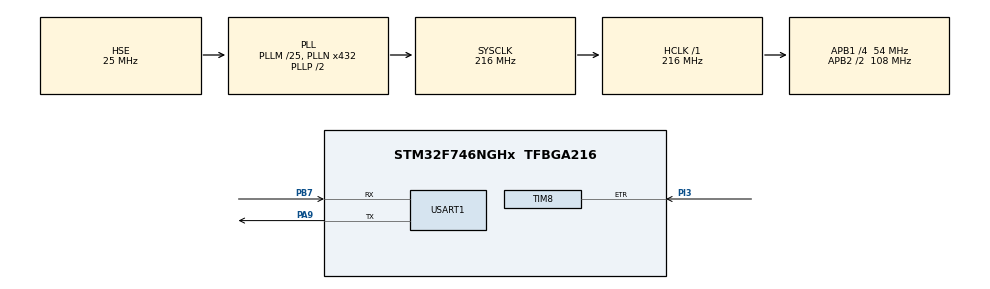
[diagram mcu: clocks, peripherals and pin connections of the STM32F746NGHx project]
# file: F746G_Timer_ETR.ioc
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Mcu.Family=STM32F7
Mcu.Name=STM32F746NGHx
Mcu.Package=TFBGA216
NVIC.PriorityGroup=NVIC_PRIORITYGROUP_4
NVIC.TIM8_UP_TIM13_IRQn=true\:0\:0\:false\:false\:true\:true\:true\:true
PA13.Mode=Serial_Wire
PA13.Signal=SYS_JTMS-SWDIO
PA14.Mode=Serial_Wire
PA14.Signal=SYS_JTCK-SWCLK
PA9.Mode=Asynchronous
PA9.Signal=USART1_TX
PB7.Mode=Asynchronous
PB7.Signal=USART1_RX
PH0/OSC_IN.Mode=HSE-External-Oscillator
PH0/OSC_IN.Signal=RCC_OSC_IN
PH1/OSC_OUT.Mode=HSE-External-Oscillator
PH1/OSC_OUT.Signal=RCC_OSC_OUT
PI3.Signal=S_TIM8_ETR
ProjectManager.HeapSize=0x200
ProjectManager.StackSize=0x400
ProjectManager.TargetToolchain=STM32CubeIDE
RCC.AHBFreq_Value=216000000
RCC.APB1CLKDivider=RCC_HCLK_DIV4
RCC.APB1Freq_Value=54000000
RCC.APB1TimFreq_Value=108000000
RCC.APB2CLKDivider=RCC_HCLK_DIV2
RCC.APB2Freq_Value=108000000
RCC.APB2TimFreq_Value=216000000
RCC.CortexFreq_Value=216000000
RCC.HCLKFreq_Value=216000000
RCC.HSE_VALUE=25000000
RCC.HSI_VALUE=16000000
RCC.LSE_VALUE=32768
RCC.PLLM=25
RCC.PLLN=432
RCC.PLLSourceVirtual=RCC_PLLSOURCE_HSE
RCC.SYSCLKFreq_VALUE=216000000
RCC.SYSCLKSource=RCC_SYSCLKSOURCE_PLLCLK
RCC.USBFreq_Value=216000000
RCC.VCOOutputFreq_Value=432000000
SH.S_TIM8_ETR.0=TIM8_ETR,ClockSourceETR_Mode2
TIM8.Period=9
USART1.VirtualMode-Asynchronous=VM_ASYNC
board=STM32F746G-DISCO

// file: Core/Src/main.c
/* USER CODE BEGIN Header */
/**
  ******************************************************************************
  * @file           : main.c
  * @brief          : Main program body
  ******************************************************************************
  * @attention
  *
  * Copyright (c) 2023 STMicroelectronics.
  * All rights reserved.
  *
  * This software is licensed under terms that can be found in the LICENSE file
  * in the root directory of this software component.
  * If no LICENSE file comes with this software, it is provided AS-IS.
  *
  ******************************************************************************
  */
/* USER CODE END Header */
#include "main.h"
#include "tim.h"
#include "usart.h"
#include "gpio.h"

/* USER CODE BEGIN Includes */
#include <stdio.h>
/* USER CODE END Includes */

/* USER CODE BEGIN PV */
uint8_t end_msg[35] = "Overflow Reached! Counter Reset!\n\r";
/* USER CODE END PV */

void SystemClock_Config(void);
/* USER CODE BEGIN PFP */
#ifdef __GNUC__
/* With GCC/RAISONANCE, small printf (option LD Linker->Libraries->Small printf
set to 'Yes') calls __io_putchar() */
#define PUTCHAR_PROTOTYPE int __io_putchar(int ch)
#else
#define PUTCHAR_PROTOTYPE int fputc(int ch, FILE *f)
#endif /* __GNUC__ */
/* USER CODE END PFP */

int main(void)
{
  /* USER CODE BEGIN 1 */
	uint16_t ticks = 0;
  /* USER CODE END 1 */

  /* MCU Configuration--------------------------------------------------------*/

  /* Reset of all peripherals, Initializes the Flash interface and the Systick. */
  HAL_Init();

  /* Configure the system clock */
  SystemClock_Config();

  /* Initialize all configured peripherals */
  MX_GPIO_Init();
  MX_TIM8_Init();
  MX_USART1_UART_Init();
  /* USER CODE BEGIN 2 */
  HAL_TIM_Base_Start_IT(&htim8);
  /* USER CODE END 2 */

  /* Infinite loop */
  while (1)
  {

    /* USER CODE BEGIN 3 */
    // Read The Counter Ticks Register
	ticks = TIM8->CNT;
	// Print The Ticks Count Via UART1
	printf("Ticks = %d\n\r", ticks);
	HAL_Delay(250);
  }
  /* USER CODE END 3 */
}

void SystemClock_Config(void)
{
  RCC_OscInitTypeDef RCC_OscInitStruct = {0};
  RCC_ClkInitTypeDef RCC_ClkInitStruct = {0};

  /** Configure the main internal regulator output voltage
  */
  __HAL_RCC_PWR_CLK_ENABLE();
  __HAL_PWR_VOLTAGESCALING_CONFIG(PWR_REGULATOR_VOLTAGE_SCALE1);

  /** Initializes the RCC Oscillators according to the specified parameters
  * in the RCC_OscInitTypeDef structure.
  */
  RCC_OscInitStruct.OscillatorType = RCC_OSCILLATORTYPE_HSE;
  RCC_OscInitStruct.HSEState = RCC_HSE_ON;
  RCC_OscInitStruct.PLL.PLLState = RCC_PLL_ON;
  RCC_OscInitStruct.PLL.PLLSource = RCC_PLLSOURCE_HSE;
  RCC_OscInitStruct.PLL.PLLM = 25;
  RCC_OscInitStruct.PLL.PLLN = 432;
  RCC_OscInitStruct.PLL.PLLP = RCC_PLLP_DIV2;
  RCC_OscInitStruct.PLL.PLLQ = 2;
  if (HAL_RCC_OscConfig(&RCC_OscInitStruct) != HAL_OK)
  {
    Error_Handler();
  }

  /** Activate the Over-Drive mode
  */
  if (HAL_PWREx_EnableOverDrive() != HAL_OK)
  {
    Error_Handler();
  }

  /** Initializes the CPU, AHB and APB buses clocks
  */
  RCC_ClkInitStruct.ClockType = RCC_CLOCKTYPE_HCLK|RCC_CLOCKTYPE_SYSCLK
                              |RCC_CLOCKTYPE_PCLK1|RCC_CLOCKTYPE_PCLK2;
  RCC_ClkInitStruct.SYSCLKSource = RCC_SYSCLKSOURCE_PLLCLK;
  RCC_ClkInitStruct.AHBCLKDivider = RCC_SYSCLK_DIV1;
  RCC_ClkInitStruct.APB1CLKDivider = RCC_HCLK_DIV4;
  RCC_ClkInitStruct.APB2CLKDivider = RCC_HCLK_DIV2;

  if (HAL_RCC_ClockConfig(&RCC_ClkInitStruct, FLASH_LATENCY_7) != HAL_OK)
  {
    Error_Handler();
  }
}

/* USER CODE BEGIN 4 */
PUTCHAR_PROTOTYPE
{
/* Place your implementation of fputc here */
/* e.g. write a character to the USART1 and Loop until the end of transmission */
	HAL_UART_Transmit(&huart1, (uint8_t *)&ch, 1, 100);
	return ch;
}
// Counter Overflow ISR Handler
void HAL_TIM_PeriodElapsedCallback(TIM_HandleTypeDef* htim)
{
    HAL_UART_Transmit(&huart1, (uint8_t *)end_msg, sizeof(end_msg), 100);
}
/* USER CODE END 4 */

void Error_Handler(void)
{
  __disable_irq();
  while (1)
  {
  }
}
